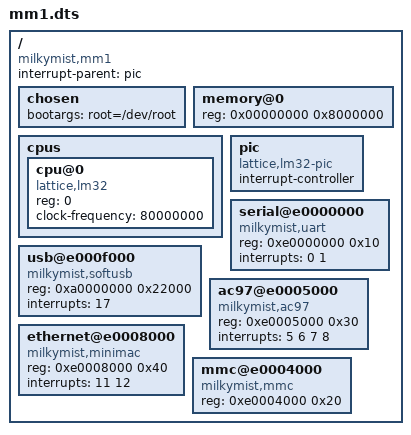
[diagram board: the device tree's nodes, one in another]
/dts-v1/;
/ {
	compatible = "milkymist,mm1";
	#address-cells = <1>;
	#size-cells = <1>;
	interrupt-parent = <&pic>;

	chosen {
		bootargs = "root=/dev/root";
	};

	memory@0 {
		device_type = "memory";
		reg = <0x00000000 0x8000000>;
	};

	cpus {
		#address-cells = <1>;
		#size-cells = <0>;
		cpu@0 {
			compatible = "lattice,lm32";
			reg = <0>;
			clock-frequency = <80000000>;
		};
	};

	pic: pic {
		compatible = "lattice,lm32-pic";
		#interrupt-cells = <1>;
		interrupt-controller;
	};

	serial@e0000000 {
		compatible = "milkymist,uart";
		reg = <0xe0000000 0x10>;
		interrupts = <0 1>;
	};

	usb@e000f000 {
		compatible = "milkymist,softusb";
		reg = <0xa0000000 0x22000>;
		interrupts = <17>;
	};

	ac97@e0005000 {
		compatible = "milkymist,ac97";
		reg = <0xe0005000 0x30>;
		interrupts = <5 6 7 8>;
	};

	ethernet@e0008000 {
		compatible = "milkymist,minimac";
		reg = <0xe0008000 0x40>;
		interrupts = <11 12>;
	};

	mmc@e0004000 {
		compatible = "milkymist,mmc";
		reg = <0xe0004000 0x20>;
	};
};

